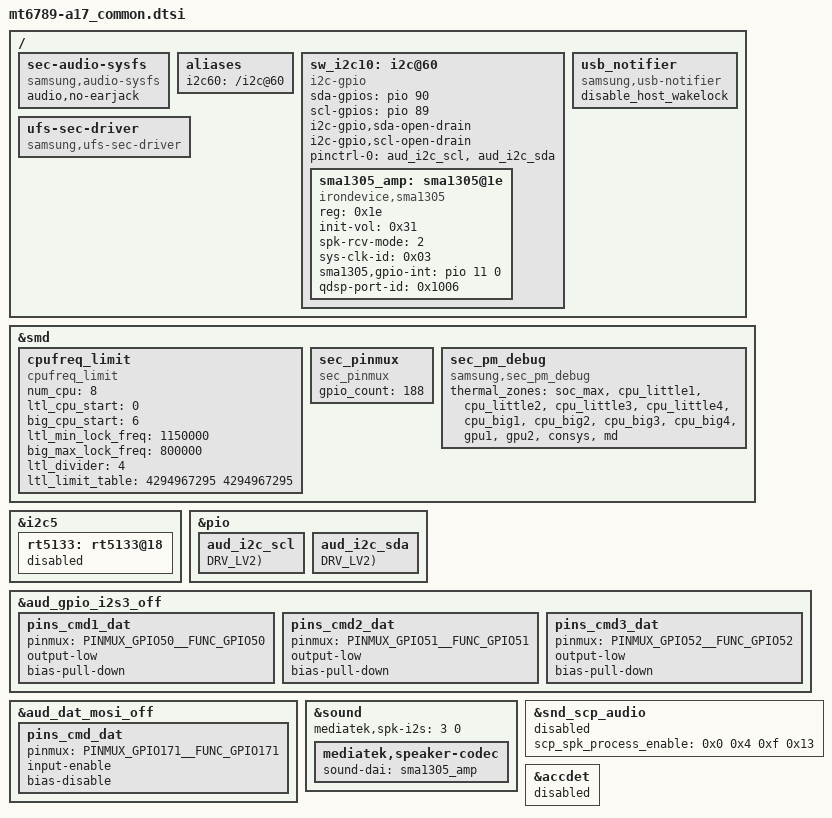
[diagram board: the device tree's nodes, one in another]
/* Generated by Samsung for MTK vendor board
 * If these files should be changed, then please make a sync with MTK
*/

/* Add Samsung configuration over here */
#include "../mt6789_wakeup_cpu_allocator.dtsi"

/ {
	fragment@model {
		target-path = "/";
		__overlay__ {
			sec-audio-sysfs {
				compatible = "samsung,audio-sysfs";
				status = "okay";
				audio,no-earjack;
				/* audio,num-amp = <1>; */
			};
			aliases {
				i2c60 = "/i2c@60";
			};
			sw_i2c10: i2c@60 {
				status = "okay";
			};
			usb_notifier {
				compatible = "samsung,usb-notifier";
				disable_host_wakelock;
			};
			ufs-sec-driver {
				compatible = "samsung,ufs-sec-driver";
				status = "okay";
			};
		};
	};
};

&smd {
	cpufreq_limit {
		status = "okay";
		compatible = "cpufreq_limit";

		num_cpu = <8>;
		ltl_cpu_start = <0>;
		big_cpu_start = <6>;
		ltl_min_lock_freq = <1150000>;
		big_max_lock_freq = <800000>;
		ltl_divider = <4>;

		ltl_limit_table = <
			4294967295 4294967295
		>;
	};

	sec_pinmux {
		status = "okay";
		compatible = "sec_pinmux";

		gpio_count = <188>;
	};

	sec_pm_debug {
		status = "okay";
		compatible = "samsung,sec_pm_debug";

		thermal_zones = "soc_max",
						"cpu_little1", "cpu_little2", "cpu_little3", "cpu_little4",
						"cpu_big1", "cpu_big2", "cpu_big3", "cpu_big4",
						"gpu1", "gpu2", "consys", "md";
	};
};

&i2c5 {
	rt5133: rt5133@18 {
		status = "disabled";
	};
};

&pio{
	aud_i2c_scl: aud_i2c_scl{
		GPIO_CONFIG_PUD_DRV(AP, pio, 89, FUNC_OUTPUT, PULL_NONE, DRV_LV2);
	};
	aud_i2c_sda: aud_i2c_sda{
		GPIO_CONFIG_PUD_DRV(AP, pio, 90, FUNC_OUTPUT, PULL_NONE, DRV_LV2);
	};
};

&sw_i2c10 {
	compatible = "i2c-gpio";
	sda-gpios = <&pio 90 (GPIO_ACTIVE_HIGH|GPIO_OPEN_DRAIN)>;
	scl-gpios = <&pio 89 (GPIO_ACTIVE_HIGH|GPIO_OPEN_DRAIN)>;
	#address-cells = <1>;
	#size-cells = <0>;
	#gpio-cells = <2>;
	i2c-gpio,sda-open-drain;
	i2c-gpio,scl-open-drain;
	pinctrl-names = "default";
	pinctrl-0 = <&aud_i2c_scl &aud_i2c_sda>;
	status = "okay";
	sma1305_amp: sma1305@1e {
		#sound-dai-cells = <0>;
		compatible = "irondevice,sma1305";
		reg = <0x1e>;
		init-vol = <0x31>;
		//stereo-two-chip;
		/* SPK_4.0W_MODE   : 0x00,
		 * SPK_4.5W_MODE   : 0x01,
		 * SPK_6.0W_MODE   : 0x02,
		 * RCV_0.1W_MODE   : 0x03,
		 * RCV_0.5W_MODE   : 0x04,
		 */
		spk-rcv-mode = <2>;
		/* EXTERNAL_CLOCK_19_2   : 0x00,
		 * EXTERNAL_CLOCK_24_576 : 0x01,
		 * PLL_CLKIN_MCLK        : 0x02,
		 * PLL_CLKIN_BCLK        : 0x03
		 */
		sys-clk-id = <0x03>;
		sma1305,gpio-int= <&pio 11 0>;
		qdsp-port-id = <0x1006>; /* AFE_PORT_ID_QUATERNARY_MI2S_RX */
		/* temp-gain-table = <0xF1 0x36 1>,<0xFB 0x35 0>,
				  <0xFF 0x34 0>,<0x05 0x33 0>,
				  <0x0A 0x32 0>,<0x0F 0x31 0>,
				  <0x14 0x30 0>; */
		status = "okay";
	};
};

&aud_gpio_i2s3_off {
	pins_cmd1_dat {
		pinmux = <PINMUX_GPIO50__FUNC_GPIO50>;
		output-low;
		bias-pull-down;
	};
	pins_cmd2_dat {
		pinmux = <PINMUX_GPIO51__FUNC_GPIO51>;
		output-low;
		bias-pull-down;
	};
	pins_cmd3_dat {
		pinmux = <PINMUX_GPIO52__FUNC_GPIO52>;
		output-low;
		bias-pull-down;
	};
};

&aud_dat_mosi_off {
	pins_cmd_dat {
		pinmux = <PINMUX_GPIO171__FUNC_GPIO171>;
		input-enable;
		bias-disable;
	};
};

&sound {
	mediatek,spk-i2s = <3 0>;
	mediatek,speaker-codec {
		sound-dai = <&sma1305_amp>;
	};
};

&snd_scp_audio {
	/* feature : $enable $dl_mem $ul_mem $ref_mem $size */
	scp_spk_process_enable = <0x0 0x4 0xf 0x13>;
	status = "disabled";
};

&accdet {
	status = "disabled";
};
